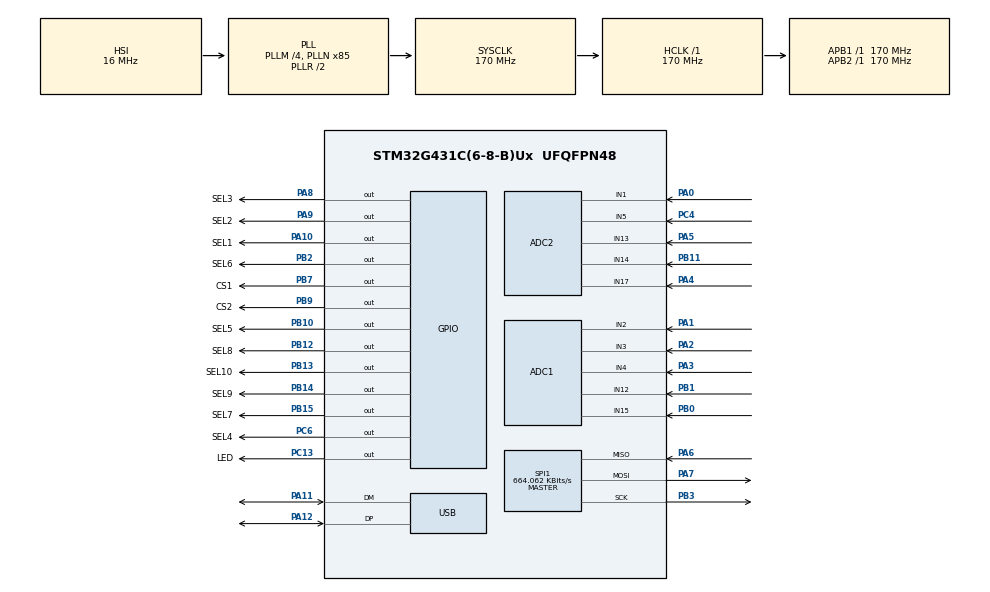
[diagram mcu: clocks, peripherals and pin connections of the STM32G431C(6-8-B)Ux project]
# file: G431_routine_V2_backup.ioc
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ADC1.Channel-0\#ChannelRegularConversion=ADC_CHANNEL_12
ADC1.Channel-1\#ChannelRegularConversion=ADC_CHANNEL_15
ADC1.Channel-2\#ChannelRegularConversion=ADC_CHANNEL_4
ADC1.Channel-3\#ChannelRegularConversion=ADC_CHANNEL_3
ADC1.Channel-4\#ChannelRegularConversion=ADC_CHANNEL_2
ADC1.ContinuousConvMode=ENABLE
ADC1.DMAContinuousRequests=ENABLE
ADC1.NbrOfConversion=5
ADC1.NbrOfConversionFlag=1
ADC1.OffsetNumber-0\#ChannelRegularConversion=ADC_OFFSET_NONE
ADC1.OffsetNumber-1\#ChannelRegularConversion=ADC_OFFSET_NONE
ADC1.OffsetNumber-2\#ChannelRegularConversion=ADC_OFFSET_NONE
ADC1.OffsetNumber-3\#ChannelRegularConversion=ADC_OFFSET_NONE
ADC1.OffsetNumber-4\#ChannelRegularConversion=ADC_OFFSET_NONE
ADC1.Rank-0\#ChannelRegularConversion=1
ADC1.Rank-1\#ChannelRegularConversion=2
ADC1.Rank-2\#ChannelRegularConversion=3
ADC1.Rank-3\#ChannelRegularConversion=4
ADC1.Rank-4\#ChannelRegularConversion=5
ADC1.SamplingTime-0\#ChannelRegularConversion=ADC_SAMPLETIME_247CYCLES_5
ADC1.SamplingTime-1\#ChannelRegularConversion=ADC_SAMPLETIME_247CYCLES_5
ADC1.SamplingTime-2\#ChannelRegularConversion=ADC_SAMPLETIME_247CYCLES_5
ADC1.SamplingTime-3\#ChannelRegularConversion=ADC_SAMPLETIME_247CYCLES_5
ADC1.SamplingTime-4\#ChannelRegularConversion=ADC_SAMPLETIME_247CYCLES_5
ADC1.master=1
ADC2.Channel-1\#ChannelRegularConversion=ADC_CHANNEL_14
ADC2.Channel-2\#ChannelRegularConversion=ADC_CHANNEL_5
ADC2.Channel-3\#ChannelRegularConversion=ADC_CHANNEL_13
ADC2.Channel-4\#ChannelRegularConversion=ADC_CHANNEL_17
ADC2.Channel-5\#ChannelRegularConversion=ADC_CHANNEL_1
ADC2.ContinuousConvMode=ENABLE
ADC2.DMAContinuousRequests=ENABLE
ADC2.NbrOfConversion=5
ADC2.NbrOfConversionFlag=1
ADC2.OffsetNumber-1\#ChannelRegularConversion=ADC_OFFSET_NONE
ADC2.OffsetNumber-2\#ChannelRegularConversion=ADC_OFFSET_NONE
ADC2.OffsetNumber-3\#ChannelRegularConversion=ADC_OFFSET_NONE
ADC2.OffsetNumber-4\#ChannelRegularConversion=ADC_OFFSET_NONE
ADC2.OffsetNumber-5\#ChannelRegularConversion=ADC_OFFSET_NONE
ADC2.Rank-1\#ChannelRegularConversion=1
ADC2.Rank-2\#ChannelRegularConversion=2
ADC2.Rank-3\#ChannelRegularConversion=3
ADC2.Rank-4\#ChannelRegularConversion=4
ADC2.Rank-5\#ChannelRegularConversion=5
ADC2.SamplingTime-1\#ChannelRegularConversion=ADC_SAMPLETIME_247CYCLES_5
ADC2.SamplingTime-2\#ChannelRegularConversion=ADC_SAMPLETIME_247CYCLES_5
ADC2.SamplingTime-3\#ChannelRegularConversion=ADC_SAMPLETIME_247CYCLES_5
ADC2.SamplingTime-4\#ChannelRegularConversion=ADC_SAMPLETIME_247CYCLES_5
ADC2.SamplingTime-5\#ChannelRegularConversion=ADC_SAMPLETIME_247CYCLES_5
Dma.ADC1.0.Direction=DMA_PERIPH_TO_MEMORY
Dma.ADC1.0.EventEnable=DISABLE
Dma.ADC1.0.Instance=DMA1_Channel1
Dma.ADC1.0.MemDataAlignment=DMA_MDATAALIGN_HALFWORD
Dma.ADC1.0.MemInc=DMA_MINC_ENABLE
Dma.ADC1.0.Mode=DMA_CIRCULAR
Dma.ADC1.0.PeriphDataAlignment=DMA_PDATAALIGN_HALFWORD
Dma.ADC1.0.PeriphInc=DMA_PINC_DISABLE
Dma.ADC1.0.Polarity=HAL_DMAMUX_REQ_GEN_RISING
Dma.ADC1.0.Priority=DMA_PRIORITY_VERY_HIGH
Dma.ADC1.0.RequestNumber=1
Dma.ADC1.0.SignalID=NONE
Dma.ADC1.0.SyncEnable=DISABLE
Dma.ADC1.0.SyncPolarity=HAL_DMAMUX_SYNC_NO_EVENT
Dma.ADC1.0.SyncRequestNumber=1
Dma.ADC1.0.SyncSignalID=NONE
Dma.ADC2.1.Direction=DMA_PERIPH_TO_MEMORY
Dma.ADC2.1.EventEnable=DISABLE
Dma.ADC2.1.Instance=DMA2_Channel1
Dma.ADC2.1.MemDataAlignment=DMA_MDATAALIGN_HALFWORD
Dma.ADC2.1.MemInc=DMA_MINC_ENABLE
Dma.ADC2.1.Mode=DMA_CIRCULAR
Dma.ADC2.1.PeriphDataAlignment=DMA_PDATAALIGN_HALFWORD
Dma.ADC2.1.PeriphInc=DMA_PINC_DISABLE
Dma.ADC2.1.Polarity=HAL_DMAMUX_REQ_GEN_RISING
Dma.ADC2.1.Priority=DMA_PRIORITY_VERY_HIGH
Dma.ADC2.1.RequestNumber=1
Dma.ADC2.1.SignalID=NONE
Dma.ADC2.1.SyncEnable=DISABLE
Dma.ADC2.1.SyncPolarity=HAL_DMAMUX_SYNC_NO_EVENT
Dma.ADC2.1.SyncRequestNumber=1
Dma.ADC2.1.SyncSignalID=NONE
Dma.Request0=ADC1
Dma.Request1=ADC2
FREERTOS.INCLUDE_vTaskDelayUntil=1
FREERTOS.Tasks01=defaultTask,0,512,StartDefaultTask,Default,NULL,Dynamic,NULL,NULL;ledTask,-3,128,LedTask,Default,NULL,Dynamic,NULL,NULL;acquisitionTask,3,256,AcquisitionTask,Default,NULL,Dynamic,NULL,NULL
FREERTOS.configTOTAL_HEAP_SIZE=10240
Mcu.Family=STM32G4
Mcu.Name=STM32G431C(6-8-B)Ux
Mcu.Package=UFQFPN48
NVIC.DMA1_Channel1_IRQn=true\:5\:0\:false\:false\:true\:true\:false\:true\:true
NVIC.DMA2_Channel1_IRQn=true\:5\:0\:false\:false\:true\:false\:false\:true\:true
NVIC.PriorityGroup=NVIC_PRIORITYGROUP_4
NVIC.TIM1_TRG_COM_TIM17_IRQn=true\:15\:0\:false\:false\:true\:false\:false\:true\:true
NVIC.TimeBase=TIM1_TRG_COM_TIM17_IRQn
NVIC.TimeBaseIP=TIM17
NVIC.USB_LP_IRQn=true\:5\:0\:false\:false\:true\:true\:false\:true\:true
PA0.Mode=IN1-Single-Ended
PA0.Signal=ADC2_IN1
PA1.Mode=IN2-Single-Ended
PA1.Signal=ADC1_IN2
PA10.GPIO_Label=SEL1
PA10.GPIO_ModeDefaultOutputPP=GPIO_MODE_OUTPUT_PP
PA10.GPIO_PuPd=GPIO_PULLUP
PA10.GPIO_Speed=GPIO_SPEED_FREQ_VERY_HIGH
PA10.PinState=GPIO_PIN_SET
PA10.Signal=GPIO_Output
PA11.Mode=Device
PA11.Signal=USB_DM
PA12.Mode=Device
PA12.Signal=USB_DP
PA13.Mode=Serial_Wire
PA13.Signal=SYS_JTMS-SWDIO
PA14.Mode=Serial_Wire
PA14.Signal=SYS_JTCK-SWCLK
PA2.Mode=IN3-Single-Ended
PA2.Signal=ADC1_IN3
PA3.Mode=IN4-Single-Ended
PA3.Signal=ADC1_IN4
PA4.Mode=IN17-Single-Ended
PA4.Signal=ADC2_IN17
PA5.Mode=IN13-Single-Ended
PA5.Signal=ADC2_IN13
PA6.Mode=Full_Duplex_Master
PA6.Signal=SPI1_MISO
PA7.Mode=Full_Duplex_Master
PA7.Signal=SPI1_MOSI
PA8.GPIO_Label=SEL3
PA8.GPIO_ModeDefaultOutputPP=GPIO_MODE_OUTPUT_PP
PA8.GPIO_PuPd=GPIO_PULLUP
PA8.GPIO_Speed=GPIO_SPEED_FREQ_VERY_HIGH
PA8.PinState=GPIO_PIN_SET
PA8.Signal=GPIO_Output
PA9.GPIO_Label=SEL2
PA9.GPIO_ModeDefaultOutputPP=GPIO_MODE_OUTPUT_PP
PA9.GPIO_PuPd=GPIO_PULLUP
PA9.GPIO_Speed=GPIO_SPEED_FREQ_VERY_HIGH
PA9.PinState=GPIO_PIN_SET
PA9.Signal=GPIO_Output
PB0.Mode=IN15-Single-Ended
PB0.Signal=ADC1_IN15
PB1.Mode=IN12-Single-Ended
PB1.Signal=ADC1_IN12
PB10.GPIO_Label=SEL5
PB10.GPIO_ModeDefaultOutputPP=GPIO_MODE_OUTPUT_PP
PB10.GPIO_PuPd=GPIO_PULLUP
PB10.GPIO_Speed=GPIO_SPEED_FREQ_VERY_HIGH
PB10.PinState=GPIO_PIN_SET
PB10.Signal=GPIO_Output
PB11.Mode=IN14-Single-Ended
PB11.Signal=ADC2_IN14
PB12.GPIO_Label=SEL8
PB12.GPIO_ModeDefaultOutputPP=GPIO_MODE_OUTPUT_PP
PB12.GPIO_PuPd=GPIO_PULLUP
PB12.GPIO_Speed=GPIO_SPEED_FREQ_VERY_HIGH
PB12.PinState=GPIO_PIN_SET
PB12.Signal=GPIO_Output
PB13.GPIO_Label=SEL10
PB13.GPIO_ModeDefaultOutputPP=GPIO_MODE_OUTPUT_PP
PB13.GPIO_PuPd=GPIO_PULLUP
PB13.GPIO_Speed=GPIO_SPEED_FREQ_VERY_HIGH
PB13.PinState=GPIO_PIN_SET
PB13.Signal=GPIO_Output
PB14.GPIO_Label=SEL9
PB14.GPIO_ModeDefaultOutputPP=GPIO_MODE_OUTPUT_PP
PB14.GPIO_PuPd=GPIO_PULLUP
PB14.GPIO_Speed=GPIO_SPEED_FREQ_VERY_HIGH
PB14.PinState=GPIO_PIN_SET
PB14.Signal=GPIO_Output
PB15.GPIO_Label=SEL7
PB15.GPIO_ModeDefaultOutputPP=GPIO_MODE_OUTPUT_PP
PB15.GPIO_PuPd=GPIO_PULLUP
PB15.GPIO_Speed=GPIO_SPEED_FREQ_VERY_HIGH
PB15.PinState=GPIO_PIN_SET
PB15.Signal=GPIO_Output
PB2.GPIO_Label=SEL6
PB2.GPIO_ModeDefaultOutputPP=GPIO_MODE_OUTPUT_PP
PB2.GPIO_PuPd=GPIO_PULLUP
PB2.GPIO_Speed=GPIO_SPEED_FREQ_VERY_HIGH
PB2.PinState=GPIO_PIN_SET
PB2.Signal=GPIO_Output
PB3.Mode=Full_Duplex_Master
PB3.Signal=SPI1_SCK
PB7.GPIO_Label=CS1
PB7.GPIO_ModeDefaultOutputPP=GPIO_MODE_OUTPUT_PP
PB7.GPIO_PuPd=GPIO_PULLUP
PB7.GPIO_Speed=GPIO_SPEED_FREQ_VERY_HIGH
PB7.PinState=GPIO_PIN_SET
PB7.Signal=GPIO_Output
PB9.GPIO_Label=CS2
PB9.GPIO_PuPd=GPIO_PULLUP
PB9.GPIO_Speed=GPIO_SPEED_FREQ_VERY_HIGH
PB9.PinState=GPIO_PIN_SET
PB9.Signal=GPIO_Output
PC13.GPIO_Label=LED
PC13.GPIO_PuPd=GPIO_PULLUP
PC13.PinState=GPIO_PIN_SET
PC13.Signal=GPIO_Output
PC4.Mode=IN5-Single-Ended
PC4.Signal=ADC2_IN5
PC6.GPIO_Label=SEL4
PC6.GPIO_ModeDefaultOutputPP=GPIO_MODE_OUTPUT_PP
PC6.GPIO_PuPd=GPIO_PULLUP
PC6.GPIO_Speed=GPIO_SPEED_FREQ_VERY_HIGH
PC6.PinState=GPIO_PIN_SET
PC6.Signal=GPIO_Output
PF0-OSC_IN.Mode=HSE-External-Oscillator
PF0-OSC_IN.Signal=RCC_OSC_IN
PF1-OSC_OUT.Mode=HSE-External-Oscillator
PF1-OSC_OUT.Signal=RCC_OSC_OUT
ProjectManager.HeapSize=0x100
ProjectManager.StackSize=0xA00
ProjectManager.TargetToolchain=MDK-ARM V5.32
RCC.ADC12Freq_Value=170000000
RCC.AHBFreq_Value=170000000
RCC.APB1Freq_Value=170000000
RCC.APB1TimFreq_Value=170000000
RCC.APB2Freq_Value=170000000
RCC.APB2TimFreq_Value=170000000
RCC.CK48CLockSelection=RCC_USBCLKSOURCE_HSI48
RCC.CortexFreq_Value=170000000
RCC.EXTERNAL_CLOCK_VALUE=12288000
RCC.HCLKFreq_Value=170000000
RCC.HSE_VALUE=8000000
RCC.HSI48_VALUE=48000000
RCC.HSI_VALUE=16000000
RCC.LSE_VALUE=32768
RCC.PLLM=RCC_PLLM_DIV4
RCC.PLLN=85
RCC.SYSCLKFreq_VALUE=170000000
RCC.SYSCLKSource=RCC_SYSCLKSOURCE_PLLCLK
RCC.USBFreq_Value=48000000
RCC.VCOOutputFreq_Value=340000000
SPI1.BaudRatePrescaler=SPI_BAUDRATEPRESCALER_256
SPI1.CalculateBaudRate=664.062 KBits/s
SPI1.DataSize=SPI_DATASIZE_8BIT
SPI1.Direction=SPI_DIRECTION_2LINES
SPI1.Mode=SPI_MODE_MASTER
SPI1.VirtualType=VM_MASTER
TIM7.Prescaler=167
USB_DEVICE.CLASS_NAME_FS=CDC
USB_DEVICE.VirtualMode=Cdc
USB_DEVICE.VirtualModeFS=Cdc_FS
VP_FREERTOS_VS_CMSIS_V1.Mode=CMSIS_V1
VP_SYS_VS_DBSignals.Mode=DisableDeadBatterySignals
VP_SYS_VS_tim17.Mode=TIM17
VP_TIM7_VS_ClockSourceINT.Mode=Enable_Timer
VP_USB_DEVICE_VS_USB_DEVICE_CDC_FS.Mode=CDC_FS
board=custom

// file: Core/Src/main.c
/* USER CODE BEGIN Header */
/**
  ******************************************************************************
  * @file           : main.c
  * @brief          : Main program body
  ******************************************************************************
  * @attention
  *
  * Copyright (c) 2025 STMicroelectronics.
  * All rights reserved.
  *
  * This software is licensed under terms that can be found in the LICENSE file
  * in the root directory of this software component.
  * If no LICENSE file comes with this software, it is provided AS-IS.
  *
  ******************************************************************************
  */
/* USER CODE END Header */
#include "main.h"
#include "cmsis_os.h"
#include "adc.h"
#include "dma.h"
#include "spi.h"
#include "tim.h"
#include "usb_device.h"
#include "gpio.h"

void SystemClock_Config(void);
void MX_FREERTOS_Init(void);

int main(void)
{

  /* MCU Configuration--------------------------------------------------------*/

  /* Reset of all peripherals, Initializes the Flash interface and the Systick. */
  HAL_Init();

  /* Configure the system clock */
  SystemClock_Config();

  /* Initialize all configured peripherals */
  MX_GPIO_Init();
  MX_DMA_Init();
  MX_USB_Device_Init();
  MX_SPI1_Init();
  MX_ADC1_Init();
  MX_ADC2_Init();
  MX_TIM7_Init();
  /* USER CODE BEGIN 2 */
	LL_TIM_SetCounter(TIM7, 0);
//	LL_TIM_EnableIT_UPDATE(TIM7);//start TIM7 IRQ
	LL_TIM_EnableCounter(TIM7);//start TIM7
  /* USER CODE END 2 */

  /* Call init function for freertos objects (in freertos.c) */
  MX_FREERTOS_Init();

  /* Start scheduler */
  osKernelStart();

  /* We should never get here as control is now taken by the scheduler */
  /* Infinite loop */
  while (1)
  {

  }
}

void SystemClock_Config(void)
{
  RCC_OscInitTypeDef RCC_OscInitStruct = {0};
  RCC_ClkInitTypeDef RCC_ClkInitStruct = {0};

  /** Configure the main internal regulator output voltage
  */
  HAL_PWREx_ControlVoltageScaling(PWR_REGULATOR_VOLTAGE_SCALE1_BOOST);

  /** Initializes the RCC Oscillators according to the specified parameters
  * in the RCC_OscInitTypeDef structure.
  */
  RCC_OscInitStruct.OscillatorType = RCC_OSCILLATORTYPE_HSI|RCC_OSCILLATORTYPE_HSI48;
  RCC_OscInitStruct.HSIState = RCC_HSI_ON;
  RCC_OscInitStruct.HSICalibrationValue = RCC_HSICALIBRATION_DEFAULT;
  RCC_OscInitStruct.HSI48State = RCC_HSI48_ON;
  RCC_OscInitStruct.PLL.PLLState = RCC_PLL_ON;
  RCC_OscInitStruct.PLL.PLLSource = RCC_PLLSOURCE_HSI;
  RCC_OscInitStruct.PLL.PLLM = RCC_PLLM_DIV4;
  RCC_OscInitStruct.PLL.PLLN = 85;
  RCC_OscInitStruct.PLL.PLLP = RCC_PLLP_DIV2;
  RCC_OscInitStruct.PLL.PLLQ = RCC_PLLQ_DIV2;
  RCC_OscInitStruct.PLL.PLLR = RCC_PLLR_DIV2;
  if (HAL_RCC_OscConfig(&RCC_OscInitStruct) != HAL_OK)
  {
    Error_Handler();
  }

  /** Initializes the CPU, AHB and APB buses clocks
  */
  RCC_ClkInitStruct.ClockType = RCC_CLOCKTYPE_HCLK|RCC_CLOCKTYPE_SYSCLK
                              |RCC_CLOCKTYPE_PCLK1|RCC_CLOCKTYPE_PCLK2;
  RCC_ClkInitStruct.SYSCLKSource = RCC_SYSCLKSOURCE_PLLCLK;
  RCC_ClkInitStruct.AHBCLKDivider = RCC_SYSCLK_DIV1;
  RCC_ClkInitStruct.APB1CLKDivider = RCC_HCLK_DIV1;
  RCC_ClkInitStruct.APB2CLKDivider = RCC_HCLK_DIV1;

  if (HAL_RCC_ClockConfig(&RCC_ClkInitStruct, FLASH_LATENCY_4) != HAL_OK)
  {
    Error_Handler();
  }
}

void HAL_TIM_PeriodElapsedCallback(TIM_HandleTypeDef *htim)
{
  if (htim->Instance == TIM17) {
    HAL_IncTick();
  }
}

void Error_Handler(void)
{
  __disable_irq();
  while (1)
  {
  }
}
